# PRU_ICSSG0_PR1_MII_RT_PR1_MII_RT_G_CFG_REGS_G_local register map
Vendor: Texas Instruments
Peripheral module from a debugger description file (folder J7ES).
Registers are 32-bit, read-write, reset 0x0 unless marked. A register's access mark holds for its fields unless they carry their own. Offsets are as the file gives them; lines under a group give offsets from that group; [hi:lo] are bit positions; {n}, {i} and the like mark numbered series; 'fields as' and 'values as' point back to an identical list; <NAME> marks a mode.

## PRU_ICSSG0_PR1_MII_RT_PR1_MII_RT_G_CFG_REGS_G
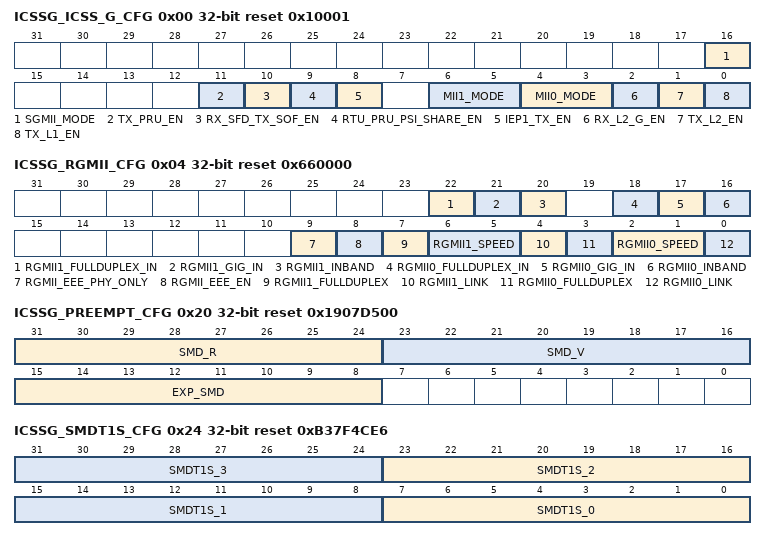
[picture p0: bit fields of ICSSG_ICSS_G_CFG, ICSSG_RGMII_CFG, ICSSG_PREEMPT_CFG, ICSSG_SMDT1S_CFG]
0x00 ICSSG_ICSS_G_CFG reset 0x10001 — ICSS_G SGMII mode is supported only for PRU_ICSSG1 instance.
  [16] SGMII_MODE — SGMII MODE0: Fiber MODE 1: SGMII MODE
  [11] TX_PRU_EN — Enable TX_PRU to gain control of MII TXL2
  [10] RX_SFD_TX_SOF_EN — Enable the remaping of tx_sof to rx_sfd if auto fwd is enable
  [9] RTU_PRU_PSI_SHARE_EN — Enable the sharing of xfr2psi attached to PRU for PRU RTU AND HW FIFO
  [8] IEP1_TX_EN — Enable IEP1 for TX Enable0: Use IEP0 CMP3_4 1: Use IEP1 CMP3_4
  [6:5] MII1_MODE — MII1 MODE0: MII 1: RGMII 2: SGMII
  [4:3] MII0_MODE — MII0 MODE0: MII 1: RGMII 2: SGMII
  [2] RX_L2_G_EN — Enable the RX L2 G features of filter frags of size TBD and backpressure RX L20: Disabled 1: Enabled
  [1] TX_L2_EN — Enable the TX L2 Fifo0: Disabled 1: Enabled
  [0] TX_L1_EN — Enable the TX L1 Fifo0: Disabled 1: Enabled
0x04 ICSSG_RGMII_CFG access per field reset 0x660000 — RGMII
  [22] RGMII1_FULLDUPLEX_IN rw — RGMII Fullduplex overide0: half 1: full
  [21] RGMII1_GIG_IN rw — RGMII GigBit Enable0: 100 Mbs 1: 1000 Mbs
  [20] RGMII1_INBAND rw — RGMII In BandEnable or Force0: InBAND is Disabled 1: InBAND Enable
  [18] RGMII0_FULLDUPLEX_IN rw — RGMII Fullduplex overide0: half 1: full
  [17] RGMII0_GIG_IN rw — RGMII GigBit Enable0: 100 Mbs 1: 1000 Mbs
  [16] RGMII0_INBAND rw — RGMII In BandEnable or Force0: InBAND is Disabled 1: InBAND Enable
  [9] RGMII_EEE_PHY_ONLY rw — RGMII Phy Only Low Power0: disable 1: enable
  [8] RGMII_EEE_EN rw — RGMII Energy Efficient Enable0: disable 1: enable
  [7] RGMII1_FULLDUPLEX ro — RGMII Fullduplex0: half duplex 1: full duplex
  [6:5] RGMII1_SPEED ro — RGMII Speed00: 10Mpbs 01: 100Mpbs 10: 1000 Mpbs
  [4] RGMII1_LINK ro — RGMII Link Status0: link is down 1: link is up
  [3] RGMII0_FULLDUPLEX ro — RGMII Fullduplex0: half duplex 1: full duplex
  [2:1] RGMII0_SPEED ro — RGMII Speed00: 10Mpbs 01: 100Mpbs 10: 1000 Mpbs
  [0] RGMII0_LINK ro — RGMII Link Status0: link is down 1: link is up
0x08 ICSSG_MAC_PRU0_0
  [31:0] MAC_PRU0_0 — MAC pru0 DA3:DA0 Used for SAV and DA match
0x0C ICSSG_MAC_PRU0_1
  [15:0] MAC_PRU0_1 — MAC pru0 DA5:DA4 Used for SAV and DA match
0x10 ICSSG_MAC_PRU1_0
  [31:0] MAC_PRU1_0 — MAC pru1 DA3:DA0 Used for SAV and DA match
0x14 ICSSG_MAC_PRU1_1
  [15:0] MAC_PRU1_1 — MAC pru1 DA5:DA4 Used for SAV and DA match
0x18 ICSSG_MAC_INTERFACE_0 — MAC_Interface_0
  [31:0] MAC_INF_0 — MAC Host interface DA3:DA0 Used for SAV and DA match
0x1C ICSSG_MAC_INTERFACE_1 — MAC_Interface_1
  [15:0] MAC_INF_1 — MAC Host interface DA5:DA4 Used for SAV and DA match
0x20 ICSSG_PREEMPT_CFG reset 0x1907D500 — Preemption_Cfg
  [31:24] SMD_R — Response frame TAG
  [23:16] SMD_V — Verification frame TAG
  [15:8] EXP_SMD — None preemptable frame start, or express frame
0x24 ICSSG_SMDT1S_CFG reset 0xB37F4CE6 — SMDType1SPreemptableFrameStartCfg
  [8n+7:8n] SMDT1S_{n} (n=0..3) — SMDT1S{n} pattern
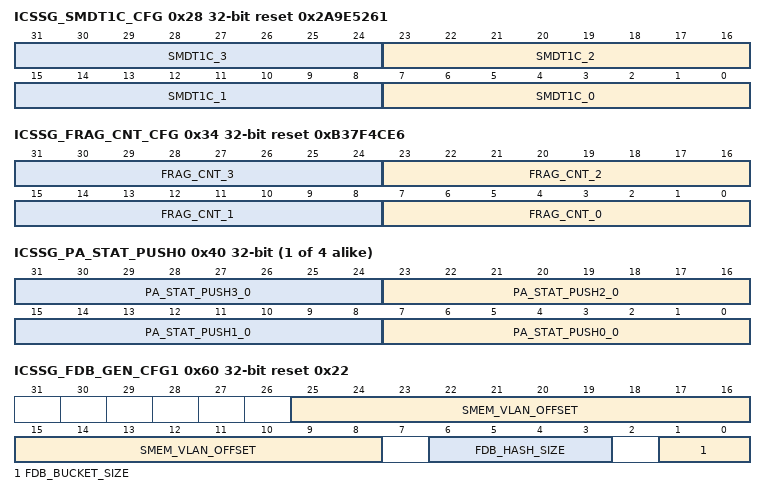
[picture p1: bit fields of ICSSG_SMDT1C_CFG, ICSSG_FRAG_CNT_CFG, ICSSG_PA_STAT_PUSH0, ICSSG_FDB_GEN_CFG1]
0x28 ICSSG_SMDT1C_CFG reset 0x2A9E5261 — SMDType1CNoneInitialFragCfg
  [8n+7:8n] SMDT1C_{n} (n=0..3) — SMDT1C{n} pattern
0x34 ICSSG_FRAG_CNT_CFG reset 0xB37F4CE6 — FragCntCfg
  [8n+7:8n] FRAG_CNT_{n} (n=0..3) — FRAG Cnt{n} pattern
{0x40+4i} ICSSG_PA_STAT_PUSH{i} (i=0..3) — PaStatPush{i}
  [8n+7:8n] PA_STAT_PUSH{n}_{i} (n=0..3) — pa stat push{n}
0x60 ICSSG_FDB_GEN_CFG1 reset 0x22 — FDBCfg1
  [25:8] SMEM_VLAN_OFFSET — SMEM VLAN FID table base address
  [6:3] FDB_HASH_SIZE — FDB hash size0:64 1:128 2:256 3:512 4:1024 5:2048
  [1:0] FDB_BUCKET_SIZE — FDB buket size0:1 1:2 2:4 3:8
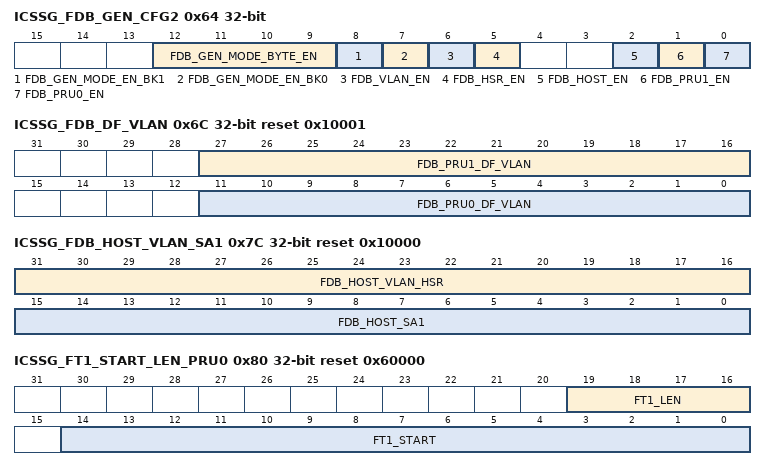
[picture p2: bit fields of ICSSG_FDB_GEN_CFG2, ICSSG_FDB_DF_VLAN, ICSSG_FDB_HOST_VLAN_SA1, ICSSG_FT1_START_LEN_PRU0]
0x64 ICSSG_FDB_GEN_CFG2 — FDBCfg2
  [12:9] FDB_GEN_MODE_BYTE_EN — FDB General Mode Byte compare size0 = 1 Byte, 15 = 16 Bytes
  [8] FDB_GEN_MODE_EN_BK1 — FDB General Mode Enable Bank1 if set PRU0/PRU1/HOST will get disabled
  [7] FDB_GEN_MODE_EN_BK0 — FDB General Mode Enable Bank0 if set PRU0/PRU1/HOST will get disabled
  [6] FDB_VLAN_EN — FDB Global VLAN Enable
  [5] FDB_HSR_EN — FDB Global HSR Enable note VLAN most be disabled
  [2] FDB_HOST_EN — FDB HOST Enable
  [1] FDB_PRU1_EN — FDB PRU1 Enable
  [0] FDB_PRU0_EN — FDB PRU0 Enable
0x68 ICSSG_FDB_GEN_STATUS size not given access not given reset not defined — FDBStatus
0x6C ICSSG_FDB_DF_VLAN reset 0x10001 — FDBDefaultPRUVLAN
  [27:16] FDB_PRU1_DF_VLAN — FDB Default VLAN for PRU1
  [11:0] FDB_PRU0_DF_VLAN — FDB Default VLAN for PRU0
0x70 ICSSG_FDB_HOST_DA0 — FDB_HOST_DA3:0_Cfg
  [31:0] FDB_HOST_DA0 — FDB HOST DA3:0
0x74 ICSSG_FDB_HOST_DA1 — FDB_HOST_DA5:4_Cfg
  [15:0] FDB_HOST_DA1 — FDB HOST DA5:4
0x78 ICSSG_FDB_HOST_SA0 — FDB_HOST_SA3:0_Cfg
  [31:0] FDB_HOST_SA0 — FDB HOST SA3:0
0x7C ICSSG_FDB_HOST_VLAN_SA1 reset 0x10000 — FDB_HOST_VLAN_SA5:4_Cfg
  [31:16] FDB_HOST_VLAN_HSR — FDB HOST VLAN[11:0] OR HSR[15:0]
  [15:0] FDB_HOST_SA1 — FDB HOST SA5:4
0x80 ICSSG_FT1_START_LEN_PRU0 reset 0x60000 — Filter1StartandLengthPru0
  [19:16] FT1_LEN — Defines the total number of Bytes Filter1 will check before Valid bit is set
  [14:0] FT1_START — Byte count start for Filter1.Any wrt will clear all Filter1 Status Bits
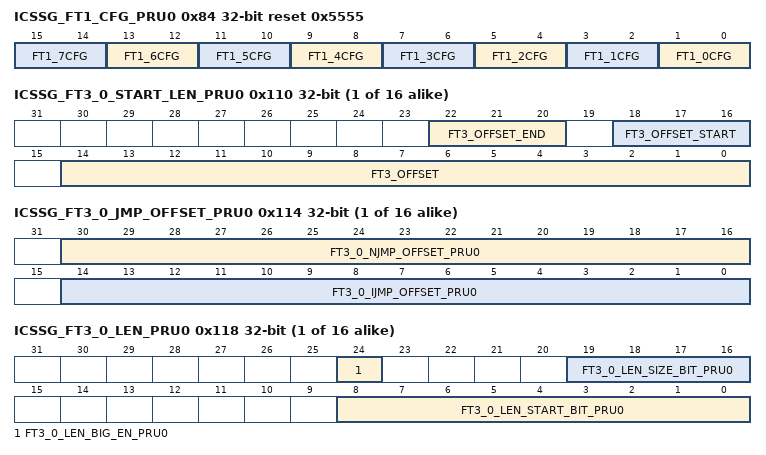
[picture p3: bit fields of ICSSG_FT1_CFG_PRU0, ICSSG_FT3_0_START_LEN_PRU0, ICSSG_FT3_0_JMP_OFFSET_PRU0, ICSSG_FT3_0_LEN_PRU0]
0x84 ICSSG_FT1_CFG_PRU0 reset 0x5555 — Filter1ConfigPru0
  [2n+1:2n] FT1_{n}CFG (n=0..7) — 0: Disabled 1: EQ 2: GT 3: LT
{0x88+0x10*i} ICSSG_FT1_{i}_DA0_PRU0 (i=0..7) — Filter1_{i}_DA0_Pru0
  [31:0] FT1_{i}_DA0 — Filter1 DA4:DA1
{0x8C+0x10*i} ICSSG_FT1_{i}_DA1_PRU0 (i=0..7) — Filter1_{i}_DA1_Pru0
  [15:0] FT1_{i}_DA1 — Filter1 DA6:DA5
{0x90+0x10*i} ICSSG_FT1_{i}_DA_MASK0_PRU0 (i=0..7) — Filter1_{i}_DA0MaskPru0
  [31:0] FT1_{i}_DA_MASK0 — Filter1 MDA4:MDA1 set to 1 to mask that bit
{0x94+0x10*i} ICSSG_FT1_{i}_DA_MASK1_PRU0 (i=0..7) — Filter1_{i}_DA1MaskPru0
  [15:0] FT1_{i}_DA_MASK1 — Filter1 MDA6:MDA5 set to 1 to mask that bit
{0x108+0x20*i} ICSSG_FT3_{i}_START_PRU0 reset 0xC (i=0..15) — Filter3_{i}_StartPru0
  [14:0] FT3_START — Byte count start for Filter3.Any wrt will clear all Filter3 Status Bits SW can read to determine next start during Auto
{0x10C+0x20*i} ICSSG_FT3_{i}_START_AUTO_PRU0 ro (i=0..15) — Filter3_{i}_StartAutoPru0
  [14:0] FT3_START_AUTO — Byte count start for Auto skip mode
{0x110+0x20*i} ICSSG_FT3_{i}_START_LEN_PRU0 (i=0..15) — Filter3_{i}_StartoffsetPru0
  [22:20] FT3_OFFSET_END — Defines which byte within FT3_[N]P[63:0] to end the compare at set the Valid flag, rule ft3_offset_end &gt;= ft3_offset_start To disable pattern compare set start and end to zero
  [18:16] FT3_OFFSET_START — Defines which byte within FT3_[N]P[63:0] to start the compare
  [14:0] FT3_OFFSET — Determine which byte to start FT3_[N]P[63:0] operation it will start on the next byte after FT3_T completes if set to zero
{0x114+0x20*i} ICSSG_FT3_{i}_JMP_OFFSET_PRU0 (i=0..15) — Filter3_{i}_JmpoffsetPru0
  [30:16] FT3_{i}_NJMP_OFFSET_PRU0 — Defines the Next Offset to compare when auto arm jump is enabled
  [14:0] FT3_{i}_IJMP_OFFSET_PRU0 — Defines the Intial Offset to compare when auto arm jump is enabled
{0x118+0x20*i} ICSSG_FT3_{i}_LEN_PRU0 (i=0..15) — Filter3_{i}_LenPru0
  [24] FT3_{i}_LEN_BIG_EN_PRU0 — Enable Big Indian on Length
  [19:16] FT3_{i}_LEN_SIZE_BIT_PRU0 — Defines number of bits to extract the length for the auto skip function
  [8:0] FT3_{i}_LEN_START_BIT_PRU0 — Defines relative bit offset from the HIT byte location upto 512 bit offset the exraction to determine the on the fly length byte offset
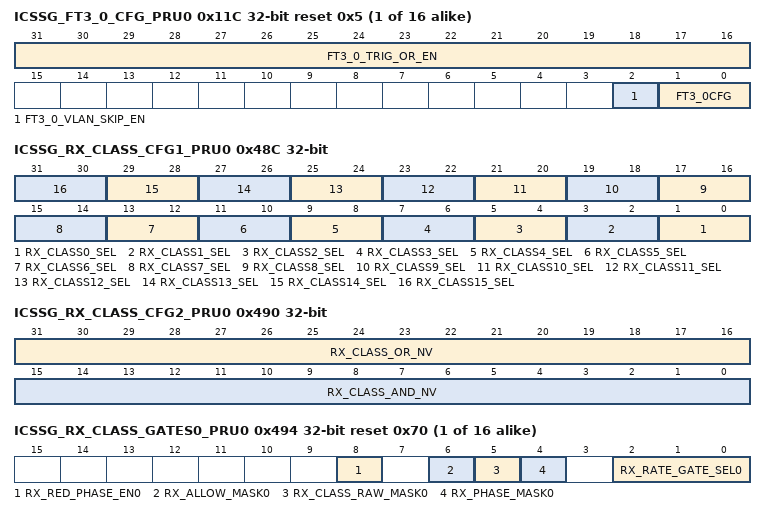
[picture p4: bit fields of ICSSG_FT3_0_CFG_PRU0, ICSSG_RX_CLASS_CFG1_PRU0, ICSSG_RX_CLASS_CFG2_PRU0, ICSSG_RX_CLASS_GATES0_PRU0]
{0x11C+0x20*i} ICSSG_FT3_{i}_CFG_PRU0 reset 0x5 (i=0..15) — Filter3_{i}_ConfigPru0
  [31:16] FT3_{i}_TRIG_OR_EN — Trigger ft3 select for auto skip enable, if one or more set the function is enabled note you can not slect the same ft3 only others
  [2] FT3_{i}_VLAN_SKIP_EN — 0: Disabled 1: Enable
  [1:0] FT3_{i}CFG — 0: Disabled 1: EQ 2: GT 3: LT
{0x120+0x20*i} ICSSG_FT3_{i}_T_PRU0 (i=0..15) — Filter3_{i}_TPru0
  [31:0] FT3_{i}_T — Filter3 T4:T1 Note if Auto Skip is enabled then Type filter is not enabled
{0x124+0x20*i} ICSSG_FT3_{i}_T_MASK_PRU0 (i=0..15) — Filter3_{i}_T_MaskPru0
  [31:0] FT3_{i}_T_MASK — Filter3 MT4:MT1 Note if Auto Skip is enabled then Type filter is not enabled set to 1 to mask that bit
{0x308+0x10*i} ICSSG_FT3_{i}_P0_PRU0 (i=0..15) — Filter3_{i}P0Pru0
  [31:0] FT3_{i}_P0 — Filter3 P4:P1
{0x30C+0x10*i} ICSSG_FT3_{i}_P1_PRU0 (i=0..15) — Filter3_{i}P1Pru0
  [31:0] FT3_{i}_P1 — Filter3 P8:P5
{0x310+0x10*i} ICSSG_FT3_{i}_P_MASK0_PRU0 (i=0..15) — Filter3P_Mask0Pru0
  [31:0] FT3_{i}_P_MASK0 — Filter3 MP4:MP1 set to 1 to mask that bit
{0x314+0x10*i} ICSSG_FT3_{i}_P_MASK1_PRU0 (i=0..15) — Filter3P_Mask1Pru0
  [31:0] FT3_{i}_P_MASK1 — Filter3 MP8:MP5 set to 1 to mask that bit
0x408 ICSSG_FT_RX_PTR_PRU0 — FilterByteCountPru0
  [31:0] FT_RX_PTR_PRU0 — RX current filter Byte Count
{0x40C+8i} ICSSG_RX_CLASS{i}_AND_EN_PRU0 (i=0..15) — rx_class{i}_and_enablesPru0
  [31:0] RX_CLASS{i}_AND_EN — rx class and enabels
{0x410+8i} ICSSG_RX_CLASS{i}_OR_EN_PRU0 (i=0..15) — rx_class{i}_or_enablesPru0
  [31:0] RX_CLASS{i}_OR_EN — rx class or enabels
0x48C ICSSG_RX_CLASS_CFG1_PRU0 — rx_class_cfg1Pru0
  [2n+1:2n] RX_CLASS{n}_SEL (n=0..15) — rx class final term selection00: OR 01: AND 10: OR AND AND OR 11: OR OR AND
0x490 ICSSG_RX_CLASS_CFG2_PRU0 — rx_class_cfg2Pru0
  [31:16] RX_CLASS_OR_NV — rx class or nv enable
  [15:0] RX_CLASS_AND_NV — rx class and nv enable
{0x494+4i} ICSSG_RX_CLASS_GATES{i}_PRU0 reset 0x70 (i=0..15) — rx_class_gate_cfgPru0
  [8] RX_RED_PHASE_EN{i} — red phase neable0: disable 1: enable
  [6] RX_ALLOW_MASK{i} — allow mask0: unmask 1: mask
  [5] RX_CLASS_RAW_MASK{i} — class raw mask0: unmask 1: mask
  [4] RX_PHASE_MASK{i} — time phase mask0: unmask 1: mask
  [2:0] RX_RATE_GATE_SEL{i} — defines which rx_rate will gate rx_class
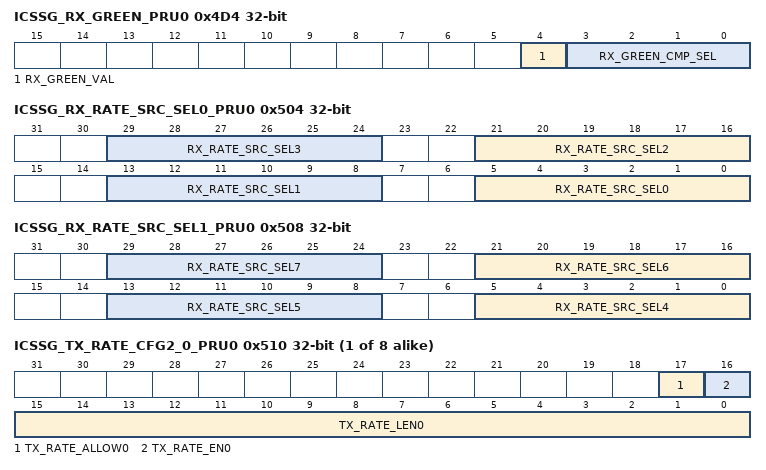
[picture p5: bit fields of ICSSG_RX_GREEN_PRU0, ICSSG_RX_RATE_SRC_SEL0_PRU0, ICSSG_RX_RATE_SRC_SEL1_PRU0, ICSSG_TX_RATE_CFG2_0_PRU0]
0x4D4 ICSSG_RX_GREEN_PRU0 access per field — RX_greenPru0
  [4] RX_GREEN_VAL ro — 0 RED 1 GREEN status
  [3:0] RX_GREEN_CMP_SEL rw — define which IEP CMP start green
0x4D8 ICSSG_SA_HASH_PRU0 — SAHashPru0
  [9:0] SA_HASH_SEED
0x4DC ICSSG_CONN_HASH_PRU0 — ConnectionHashPru0
  [9:0] CONN_HASH_SEED — Connection Hash Seed
0x4E0 ICSSG_CONN_HASH_START_PRU0 — ConnectionHashStartPru0
  [14:0] CONN_HASH_START — Connection Hash Start which 4 Bytes to hash
{0x4E4+4i} ICSSG_RX_RATE_CFG{i}_PRU0 (i=0..7) — RX_RateConfiguration{i}Pru0
  [31:0] RX_RATE_CIR_IDLE{i} — RX Rate Peak Information Rate Idle Increment Value - The number added to the PIR counter every clock cycle including EOF.The PIR counter is disabled with a zero value and packets will not be marked RED
0x504 ICSSG_RX_RATE_SRC_SEL0_PRU0 — RX_RateSourceSelect0Pru0
  [8n+5:8n] RX_RATE_SRC_SEL{n} (n=0..3) — Map which filter/flag/class hit that rate logic uses, see table for mapping
0x508 ICSSG_RX_RATE_SRC_SEL1_PRU0 — RX_RateSourceSelect1Pru0
  [8n-27:8n-32] RX_RATE_SRC_SEL{n} (n=4..7) — Map which filter/flag/class hit that rate logic uses, see table for mapping
{0x50C+8i} ICSSG_TX_RATE_CFG1_{i}_PRU0 (i=0..7) — TX_RateConfiguration1_{i}Pru0
  [31:0] TX_RATE_CIR_IDLE{i} — TX Rate Peak Information Rate Idle Increment Value - The number added to the PIR counter every clock cycle including EOF.The PIR counter is disabled with a zero value and packets will not be marked RED
{0x510+8i} ICSSG_TX_RATE_CFG2_{i}_PRU0 access per field (i=0..7) — TX_RateConfiguration2_{i}Pru0
  [17] TX_RATE_ALLOW{i} ro — TX Rate Pkt Enable
  [16] TX_RATE_EN{i} rw — TX Rate Pkt Enable
  [15:0] TX_RATE_LEN{i} rw — TX Rate Pkt Length
0x54C ICSSG_RX_STAT_GOOD_PRU0 — RXGoodFrameCountPru0
  [31:0] RX_GOOD_FRM_CNT — RX Good Frame Count Inc on none min err max err crc err odd err, Wrt subtracts
0x550 ICSSG_RX_STAT_BC_PRU0 — RXBCFrameCountPru0
  [15:0] RX_BC_FRM_CNT — RX BC Frame Count Inc on BC type, Wrt subtracts
0x554 ICSSG_RX_STAT_MC_PRU0 — RXMCFrameCountPru0
  [15:0] RX_MC_FRM_CNT — RX MC Frame Count Inc on MC type, Wrt subtracts
0x558 ICSSG_RX_STAT_CRC_ERR_PRU0 — RXCRCErrFrameCountPru0
  [15:0] RX_CRC_ERR_FRM_CNT — RX CRC Err Frame Count Inc on crc err, Wrt subtracts
0x55C ICSSG_RX_STAT_MII_ERR_PRU0 — RXMIIErrFrameCountPru0
  [15:0] RX_MII_ERR_FRM_CNT — RX MII Err Frame Count Inc on mii sgmii rgmii err, Wrt subtracts
0x560 ICSSG_RX_STAT_ODD_ERR_PRU0 — RXOddNibbleFrameCountPru0
  [15:0] RX_ODD_ERR_FRM_CNT — RX Odd Nibble Frame Count Inc on odd nibble mii, Wrt subtracts
0x564 ICSSG_RX_STAT_MAX_SIZE_PRU0 reset 0x7D0 — RXMaxSizeFramePru0
  [15:0] RX_MAX_SIZE_FRM — RX MAX Size Frame Count Limit
0x568 ICSSG_RX_STAT_MAX_ERR_PRU0 — RXMaxSizeErrFrameCountPru0
  [15:0] RX_MAX_ERR_FRM_CNT — RX MAX Size Err Frame Count Inc if &gt; than Limit, Wrt subtracts
0x56C ICSSG_RX_STAT_MIN_SIZE_PRU0 reset 0x40 — RXMinSizeFramePru0
  [15:0] RX_MIN_SIZE_FRM — RX MIN Size Frame Limit
0x570 ICSSG_RX_STAT_MIN_ERR_PRU0 — RXMinSizeErrFrameCountPru0
  [15:0] RX_MIN_ERR_FRM_CNT — RX MIN Size Frame Count Inc if &lt; than limit, Wrt subtracts
0x574 ICSSG_RX_STAT_OVERRUN_ERR_PRU0 — RXoverrunFrameCountPru0
  [15:0] RX_OVERRUN_ERR_FRM_CNT — RX L1 FIFO overflow Frame Count Inc on overflow event, Wrt subtracts
{0x578+4i} ICSSG_RX_STAT_CLASS{i}_HIT_PRU0 (i=0..15) — RXClass0
  [31:0] RX_STAT_CLASS{i}_PRU0 — RX Class{i} Hit Count, Wrt subtracts
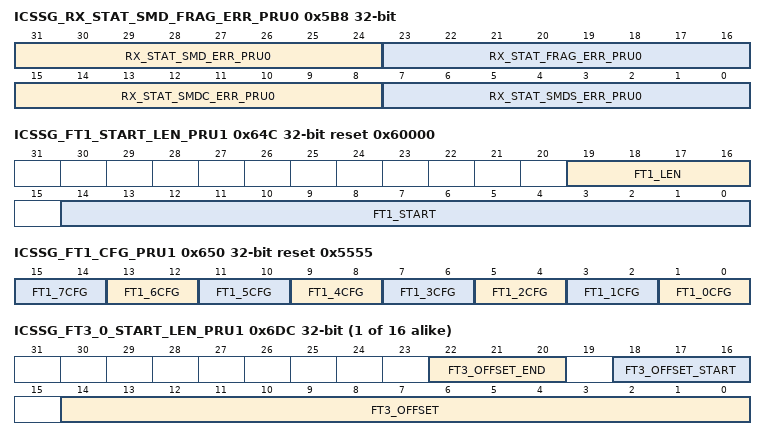
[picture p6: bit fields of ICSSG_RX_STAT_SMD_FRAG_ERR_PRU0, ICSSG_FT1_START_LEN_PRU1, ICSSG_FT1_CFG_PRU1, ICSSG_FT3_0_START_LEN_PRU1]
0x5B8 ICSSG_RX_STAT_SMD_FRAG_ERR_PRU0 — RXSMDFragErrCountPru0
  [31:24] RX_STAT_SMD_ERR_PRU0 — RX SMDS Error Count, Inc when first none 0x55 does not match any valid SMD, Wrt subtracts
  [23:16] RX_STAT_FRAG_ERR_PRU0 — RX Frag_Cnt Seq Error Count, Wrt subtracts
  [15:8] RX_STAT_SMDC_ERR_PRU0 — RX SMDCx Seq Error Count, Wrt subtracts
  [7:0] RX_STAT_SMDS_ERR_PRU0 — RX SMDSx Seq Error Count, Wrt subtracts
0x5BC ICSSG_RX_STAT_BKT1_SIZE_PRU0 reset 0x40 — RXBucket1SizeConfigPru0
  [13:0] RX_STAT_BKT1_SIZE — RX Bucket1 Byte Size
0x5C0 ICSSG_RX_STAT_BKT2_SIZE_PRU0 reset 0x80 — RXBucket2SizeConfigPru0
  [13:0] RX_STAT_BKT2_SIZE — RX Bucket2 Byte Size
0x5C4 ICSSG_RX_STAT_BKT3_SIZE_PRU0 reset 0x100 — RXBucket3SizeConfigPru0
  [13:0] RX_STAT_BKT3_SIZE — RX Bucket3 Byte Size
0x5C8 ICSSG_RX_STAT_BKT4_SIZE_PRU0 reset 0x200 — RXBucket4SizeConfigPru0
  [13:0] RX_STAT_BKT4_SIZE — RX Bucket4 Byte Size
0x5CC ICSSG_RX_STAT_64_PRU0 — RX64BSizedFrameCountPru0
  [15:0] RX_64_FRM_CNT — RX 64Byte Frame Count Inc if 64B size
0x5D0 ICSSG_RX_STAT_BKT1_PRU0 — RXBucket1SizedFrameCountPru0
  [15:0] RX_STAT_BKT1 — RX Bucket1 Frame Count Inc if &lt;= than Bucket1 Byte Size
{0x5CC+4i} ICSSG_RX_STAT_BKT{i}_PRU0 (i=2..4) — RXBucket{i}SizedFrameCountPru0
  [15:0] RX_STAT_BKT{i} — RX Bucket{i} Frame Count Inc if &lt;= than Bucket{i} Byte Size and if &gt; than Bucket{i-1} Byte Size
0x5E0 ICSSG_RX_STAT_BKT5_PRU0 — RXBucket5SizedFrameCountPru0
  [15:0] RX_STAT_BKT5 — RX Bucket5 Frame Count Inc if &gt; than Bucket4 Byte Size
0x5E4 ICSSG_RX_STAT_TOTAL_BYTES_PRU0 — RXTotalByteCountPru0
  [31:0] RX_STAT_TOTAL_BYTES_PRU — RX Total Byte Count
0x5E8 ICSSG_RXTX_STAT_TOTAL_BYTES_PRU0 — RX_TX_TotalByteCountPru0
  [31:0] RXTX_STAT_TOTAL_BYTES_PRU — RX and TX Total Byte Count
0x5EC ICSSG_TX_STAT_GOOD_PORT0 — TXGoodFrameCountPort0
  [31:0] TX_GOOD_FRM_CNT — TX Good Frame Count Inc if no min size err max size err or mii odd nibble
0x5F0 ICSSG_TX_STAT_BC_PORT0 — TXBCFrameCountPort0
  [15:0] TX_BC_FRM_CNT — TX BC Frame Count Inc if BC
0x5F4 ICSSG_TX_STAT_MC_PORT0 — TXMFrameCountPort0
  [15:0] TX_MC_FRM_CNT — TX MC Frame Count Inc if MC
0x5F8 ICSSG_TX_STAT_ODD_ERR_PORT0 — TXOddNibbleFrameCountPort0
  [15:0] TX_ODD_ERR_FRM_CNT — TX Odd Nibble Frame Count Inc if mii odd nibble
0x5FC ICSSG_TX_STAT_UNDERFLOW_ERR_PORT0 — TXUnderFlowErrCountPort0
  [15:0] TX_UNDERFLOW_CNT — TX MAX Underflow Error Cnt
0x600 ICSSG_TX_STAT_MAX_SIZE_PORT0 reset 0x7D0 — TXMaxSizeFramePort0
  [15:0] TX_MAX_SIZE_FRM — TX MAX Size Frame Count Limit
0x604 ICSSG_TX_STAT_MAX_ERR_PORT0 — TXMaxSizeErrFrameCountPort0
  [15:0] TX_MAX_ERR_FRM_CNT — TX MAX Size Err Frame Count Inc if &gt; max Limit
0x608 ICSSG_TX_STAT_MIN_SIZE_PORT0 reset 0x40 — TXMinSizeFramePort0
  [15:0] TX_MIN_SIZE_FRM — TX MIN Size Frame Count Limit
0x60C ICSSG_TX_STAT_MIN_ERR_PORT0 — TXMinSizeErrFrameCountPort0
  [15:0] TX_MIN_ERR_FRM_CNT — TX MIN Size Err Frame Count Inc if &lt; min Limit
0x610 ICSSG_TX_STAT_BKT1_SIZE_PORT0 reset 0x40 — TXBucket1SizeConfigPort0
  [13:0] TX_STAT_BKT1_SIZE — TX Bucket1 Byte Size
0x614 ICSSG_TX_STAT_BKT2_SIZE_PORT0 reset 0x80 — TXBucket2SizeConfigPort0
  [13:0] TX_STAT_BKT2_SIZE — TX Bucket2 Byte Size
0x618 ICSSG_TX_STAT_BKT3_SIZE_PORT0 reset 0x100 — TXBucket3SizeConfigPort0
  [13:0] TX_STAT_BKT3_SIZE — TX Bucket3 Byte Size
0x61C ICSSG_TX_STAT_BKT4_SIZE_PORT0 reset 0x200 — TXBucket4SizeConfigPort0
  [13:0] TX_STAT_BKT4_SIZE — TX Bucket4 Byte Size
0x620 ICSSG_TX_STAT_64_PORT0 — TX64BSizedFrameCountPort0
  [15:0] TX_64_FRM_CNT — TX 64Byte Frame Count Inc if 64B
0x624 ICSSG_TX_STAT_BKT1_PORT0 — TXBucket1SizedFrameCountPort0
  [15:0] TX_STAT_BKT1 — TX Bucket1 Inc if &lt;= than Bucket1
{0x620+4i} ICSSG_TX_STAT_BKT{i}_PORT0 (i=2..4) — TXBucket{i}SizedFrameCountPort0
  [15:0] TX_STAT_BKT{i} — TX Bucket{i} Inc if &lt;= than Bucket{i} Byte Size and if &gt; than Bucket{i-1} Byte Size
0x634 ICSSG_TX_STAT_BKT5_PORT0 — TXBucket5SizedFrameCountPort0
  [15:0] TX_STAT_BKT5 — TX Bucket5 Inc if &gt; than Bucket4 Byte Size
0x638 ICSSG_TX_STAT_TOTAL_BYTES_PORT0 — TXTotalByteCountPort0
  [31:0] TX_TOTAL_STAT_BYTES_PORT — TX Total Byte Count of all Frames
0x63C ICSSG_TX_HSR_TAG_PORT0 reset 0x892F — TXHSRTAGPort0
  [31:0] TX_HSR_TAG — HSR TAG
0x640 ICSSG_TX_HSR_SEQ_PORT0 — TXHSRSeqPort0
  [15:0] TX_HSR_SEQ — HSR Seq count.It will incr for every HSR type
0x644 ICSSG_TX_VLAN_TYPE_TAG_PORT0 reset 0x81 — TXVLANTYPETAGPort0
  [15:0] TX_VLAN_TYPE_TAG — TX VLAN Type Tag, match to enable VLAN removal
0x648 ICSSG_TX_VLAN_INS_TAG_PORT0 reset 0x1 — TXVLANINSTAGPort0
  [31:0] TX_VLAN_INS_TAG — TX VLAN Insertion
0x64C ICSSG_FT1_START_LEN_PRU1 reset 0x60000 — Filter1StartandLengthPru1
  fields as ICSSG_FT1_START_LEN_PRU0
0x650 ICSSG_FT1_CFG_PRU1 reset 0x5555 — Filter1ConfigPru1
  [2n+1:2n] FT1_{n}CFG (n=0..7) — 0: Disabled 1: EQ 2: GT 3: LT
{0x654+0x10*i} ICSSG_FT1_{i}_DA0_PRU1 (i=0..7) — Filter1_{i}_DA0_Pru1
  [31:0] FT1_{i}_DA0 — Filter1 DA4:DA1
{0x658+0x10*i} ICSSG_FT1_{i}_DA1_PRU1 (i=0..7) — Filter1_{i}_DA1_Pru1
  [15:0] FT1_{i}_DA1 — Filter1 DA6:DA5
{0x65C+0x10*i} ICSSG_FT1_{i}_DA_MASK0_PRU1 (i=0..7) — Filter1_{i}_DA0MaskPru1
  fields as ICSSG_FT1_0_DA_MASK0_PRU0
{0x660+0x10*i} ICSSG_FT1_{i}_DA_MASK1_PRU1 (i=0..7) — Filter1_{i}_DA1MaskPru1
  fields as ICSSG_FT1_0_DA_MASK1_PRU0
{0x6D4+0x20*i} ICSSG_FT3_{i}_START_PRU1 reset 0xC (i=0..15) — Filter3_{i}_StartPru1
  fields as ICSSG_FT3_0_START_PRU0
{0x6D8+0x20*i} ICSSG_FT3_{i}_START_AUTO_PRU1 ro (i=0..15) — Filter3_{i}_StartAutoPru1
  [14:0] FT3_START_AUTO — Byte count start for Auto skip mode
{0x6DC+0x20*i} ICSSG_FT3_{i}_START_LEN_PRU1 (i=0..15) — Filter3_{i}_StartoffsetPru1
  fields as ICSSG_FT3_0_START_LEN_PRU0
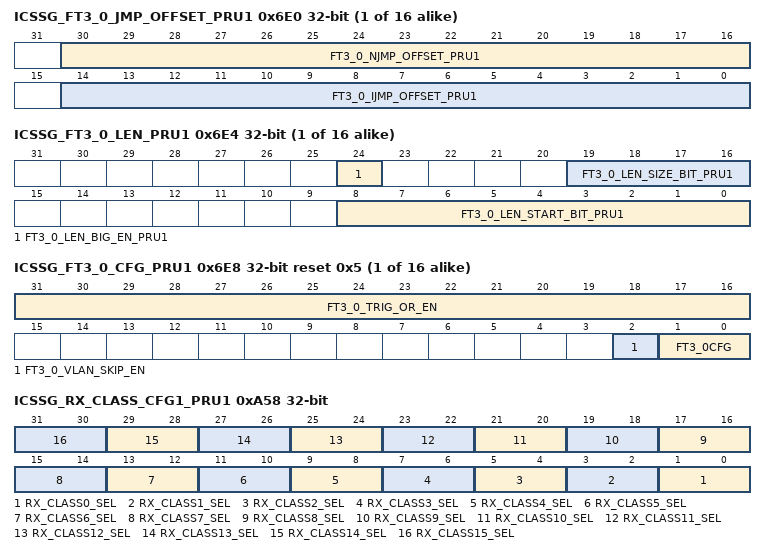
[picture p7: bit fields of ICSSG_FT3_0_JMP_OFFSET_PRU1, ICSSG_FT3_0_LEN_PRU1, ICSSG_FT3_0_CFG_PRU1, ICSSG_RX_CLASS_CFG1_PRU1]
{0x6E0+0x20*i} ICSSG_FT3_{i}_JMP_OFFSET_PRU1 (i=0..15) — Filter3_{i}_JmpoffsetPru1
  [30:16] FT3_{i}_NJMP_OFFSET_PRU1 — Defines the Next Offset to compare when auto arm jump is enabled
  [14:0] FT3_{i}_IJMP_OFFSET_PRU1 — Defines the Intial Offset to compare when auto arm jump is enabled
{0x6E4+0x20*i} ICSSG_FT3_{i}_LEN_PRU1 (i=0..15) — Filter3_{i}_LenPru1
  [24] FT3_{i}_LEN_BIG_EN_PRU1 — Enable Big Indian on Length
  [19:16] FT3_{i}_LEN_SIZE_BIT_PRU1 — Defines number of bits to extract the length for the auto skip function
  [8:0] FT3_{i}_LEN_START_BIT_PRU1 — Defines relative bit offset from the HIT byte location upto 512 bit offset the exraction to determine the on the fly length byte offset
{0x6E8+0x20*i} ICSSG_FT3_{i}_CFG_PRU1 reset 0x5 (i=0..15) — Filter3_{i}_ConfigPru1
  fields as ICSSG_FT3_0_CFG_PRU0
{0x6EC+0x20*i} ICSSG_FT3_{i}_T_PRU1 (i=0..15) — Filter3_{i}_TPru1
  fields as ICSSG_FT3_0_T_PRU0
{0x6F0+0x20*i} ICSSG_FT3_{i}_T_MASK_PRU1 (i=0..15) — Filter3_{i}_T_MaskPru1
  fields as ICSSG_FT3_0_T_MASK_PRU0
{0x8D4+0x10*i} ICSSG_FT3_{i}_P0_PRU1 (i=0..15) — Filter3_{i}P0Pru1
  [31:0] FT3_{i}_P0 — Filter3 P4:P1
{0x8D8+0x10*i} ICSSG_FT3_{i}_P1_PRU1 (i=0..15) — Filter3_{i}P1Pru1
  [31:0] FT3_{i}_P1 — Filter3 P8:P5
{0x8DC+0x10*i} ICSSG_FT3_{i}_P_MASK0_PRU1 (i=0..15) — Filter3P_Mask0Pru1
  [31:0] FT3_{i}_P_MASK0 — Filter3 MP4:MP1 set to 1 to mask that bit
{0x8E0+0x10*i} ICSSG_FT3_{i}_P_MASK1_PRU1 (i=0..15) — Filter3P_Mask1Pru1
  [31:0] FT3_{i}_P_MASK1 — Filter3 MP8:MP5 set to 1 to mask that bit
0x9D4 ICSSG_FT_RX_PTR_PRU1 — FilterByteCountPru1
  [31:0] FT_RX_PTR_PRU1 — RX current filter Byte Count
{0x9D8+8i} ICSSG_RX_CLASS{i}_AND_EN_PRU1 (i=0..15) — rx_class{i}_and_enablesPru1
  [31:0] RX_CLASS{i}_AND_EN — rx class and enabels
{0x9DC+8i} ICSSG_RX_CLASS{i}_OR_EN_PRU1 (i=0..15) — rx_class{i}_or_enablesPru1
  [31:0] RX_CLASS{i}_OR_EN — rx class or enabels
0xA58 ICSSG_RX_CLASS_CFG1_PRU1 — rx_class_cfg1Pru1
  fields as ICSSG_RX_CLASS_CFG1_PRU0
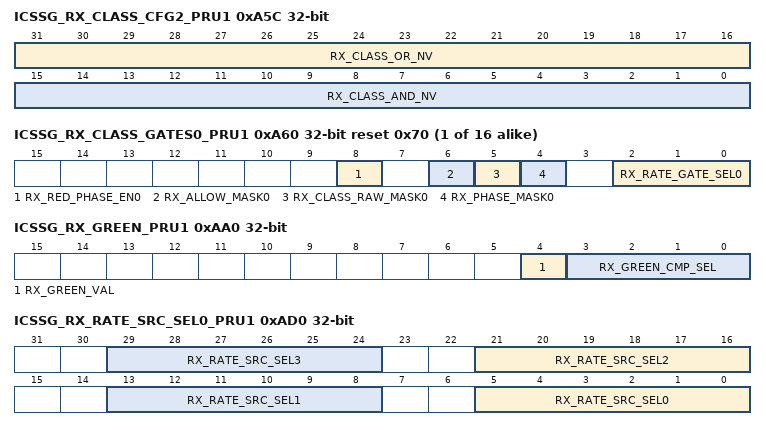
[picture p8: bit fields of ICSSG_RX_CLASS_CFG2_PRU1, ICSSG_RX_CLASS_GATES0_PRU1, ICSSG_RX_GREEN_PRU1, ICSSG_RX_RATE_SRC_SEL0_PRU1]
0xA5C ICSSG_RX_CLASS_CFG2_PRU1 — rx_class_cfg2Pru1
  fields as ICSSG_RX_CLASS_CFG2_PRU0
{0xA60+4i} ICSSG_RX_CLASS_GATES{i}_PRU1 reset 0x70 (i=0..15) — rx_class_gate_cfgPru1
  fields as ICSSG_RX_CLASS_GATES0_PRU0
0xAA0 ICSSG_RX_GREEN_PRU1 access per field — RX_greenPru1
  fields as ICSSG_RX_GREEN_PRU0
0xAA4 ICSSG_SA_HASH_PRU1 — SAHashPru1
  [9:0] SA_HASH_SEED
0xAA8 ICSSG_CONN_HASH_PRU1 — ConnectionHashPru1
  [9:0] CONN_HASH_SEED — Connection Hash Seed
0xAAC ICSSG_CONN_HASH_START_PRU1 — ConnectionHashStartPru1
  [14:0] CONN_HASH_START — Connection Hash Start which 4 Bytes to hash
{0xAB0+4i} ICSSG_RX_RATE_CFG{i}_PRU1 (i=0..7) — RX_RateConfiguration{i}Pru1
  fields as ICSSG_RX_RATE_CFG0_PRU0
0xAD0 ICSSG_RX_RATE_SRC_SEL0_PRU1 — RX_RateSourceSelect0Pru1
  fields as ICSSG_RX_RATE_SRC_SEL0_PRU0
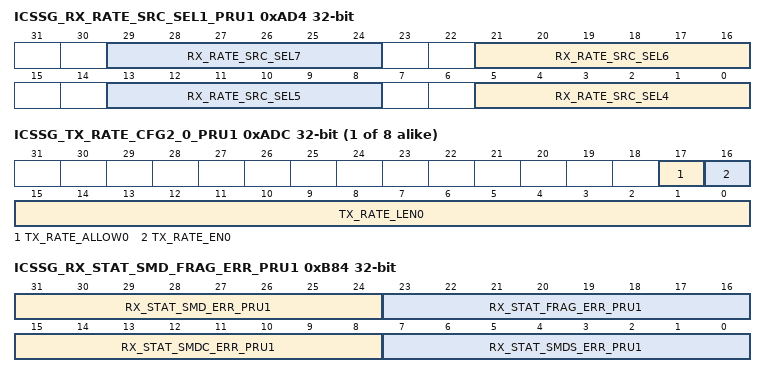
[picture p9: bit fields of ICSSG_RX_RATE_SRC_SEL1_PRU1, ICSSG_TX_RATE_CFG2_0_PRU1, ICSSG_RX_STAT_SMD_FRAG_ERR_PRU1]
0xAD4 ICSSG_RX_RATE_SRC_SEL1_PRU1 — RX_RateSourceSelect1Pru1
  fields as ICSSG_RX_RATE_SRC_SEL1_PRU0
{0xAD8+8i} ICSSG_TX_RATE_CFG1_{i}_PRU1 (i=0..7) — TX_RateConfiguration1_{i}Pru1
  fields as ICSSG_TX_RATE_CFG1_0_PRU0
{0xADC+8i} ICSSG_TX_RATE_CFG2_{i}_PRU1 access per field (i=0..7) — TX_RateConfiguration2_{i}Pru1
  fields as ICSSG_TX_RATE_CFG2_0_PRU0
0xB18 ICSSG_RX_STAT_GOOD_PRU1 — RXGoodFrameCountPru1
  fields as ICSSG_RX_STAT_GOOD_PRU0
0xB1C ICSSG_RX_STAT_BC_PRU1 — RXBCFrameCountPru1
  fields as ICSSG_RX_STAT_BC_PRU0
0xB20 ICSSG_RX_STAT_MC_PRU1 — RXMCFrameCountPru1
  fields as ICSSG_RX_STAT_MC_PRU0
0xB24 ICSSG_RX_STAT_CRC_ERR_PRU1 — RXCRCErrFrameCountPru1
  fields as ICSSG_RX_STAT_CRC_ERR_PRU0
0xB28 ICSSG_RX_STAT_MII_ERR_PRU1 — RXMIIErrFrameCountPru1
  fields as ICSSG_RX_STAT_MII_ERR_PRU0
0xB2C ICSSG_RX_STAT_ODD_ERR_PRU1 — RXOddNibbleFrameCountPru1
  fields as ICSSG_RX_STAT_ODD_ERR_PRU0
0xB30 ICSSG_RX_STAT_MAX_SIZE_PRU1 reset 0x7D0 — RXMaxSizeFramePru1
  [15:0] RX_MAX_SIZE_FRM — RX MAX Size Frame Count Limit
0xB34 ICSSG_RX_STAT_MAX_ERR_PRU1 — RXMaxSizeErrFrameCountPru1
  fields as ICSSG_RX_STAT_MAX_ERR_PRU0
0xB38 ICSSG_RX_STAT_MIN_SIZE_PRU1 reset 0x40 — RXMinSizeFramePru1
  [15:0] RX_MIN_SIZE_FRM — RX MIN Size Frame Limit
0xB3C ICSSG_RX_STAT_MIN_ERR_PRU1 — RXMinSizeErrFrameCountPru1
  fields as ICSSG_RX_STAT_MIN_ERR_PRU0
0xB40 ICSSG_RX_STAT_OVERRUN_ERR_PRU1 — RXoverrunFrameCountPru1
  fields as ICSSG_RX_STAT_OVERRUN_ERR_PRU0
{0xB44+4i} ICSSG_RX_STAT_CLASS{i}_HIT_PRU1 (i=0..15) — RXClass1
  [31:0] RX_STAT_CLASS{i}_PRU1 — RX Class{i} Hit Count, Wrt subtracts
0xB84 ICSSG_RX_STAT_SMD_FRAG_ERR_PRU1 — RXSMDFragErrCountPru1
  [31:24] RX_STAT_SMD_ERR_PRU1 — RX SMDS Error Count, Inc when first none 0x55 does not match any valid SMD, Wrt subtracts
  [23:16] RX_STAT_FRAG_ERR_PRU1 — RX Frag_Cnt Seq Error Count, Wrt subtracts
  [15:8] RX_STAT_SMDC_ERR_PRU1 — RX SMDCx Seq Error Count, Wrt subtracts
  [7:0] RX_STAT_SMDS_ERR_PRU1 — RX SMDSx Seq Error Count, Wrt subtracts
0xB88 ICSSG_RX_STAT_BKT1_SIZE_PRU1 reset 0x40 — RXBucket1SizeConfigPru1
  [13:0] RX_STAT_BKT1_SIZE — RX Bucket1 Byte Size
0xB8C ICSSG_RX_STAT_BKT2_SIZE_PRU1 reset 0x80 — RXBucket2SizeConfigPru1
  [13:0] RX_STAT_BKT2_SIZE — RX Bucket2 Byte Size
0xB90 ICSSG_RX_STAT_BKT3_SIZE_PRU1 reset 0x100 — RXBucket3SizeConfigPru1
  [13:0] RX_STAT_BKT3_SIZE — RX Bucket3 Byte Size
0xB94 ICSSG_RX_STAT_BKT4_SIZE_PRU1 reset 0x200 — RXBucket4SizeConfigPru1
  [13:0] RX_STAT_BKT4_SIZE — RX Bucket4 Byte Size
0xB98 ICSSG_RX_STAT_64_PRU1 — RX64BSizedFrameCountPru1
  [15:0] RX_64_FRM_CNT — RX 64Byte Frame Count Inc if 64B size
0xB9C ICSSG_RX_STAT_BKT1_PRU1 — RXBucket1SizedFrameCountPru1
  fields as ICSSG_RX_STAT_BKT1_PRU0
{0xB98+4i} ICSSG_RX_STAT_BKT{i}_PRU1 (i=2..4) — RXBucket{i}SizedFrameCountPru1
  fields as ICSSG_RX_STAT_BKT2_PRU0
0xBAC ICSSG_RX_STAT_BKT5_PRU1 — RXBucket5SizedFrameCountPru1
  fields as ICSSG_RX_STAT_BKT5_PRU0
0xBB0 ICSSG_RX_STAT_TOTAL_BYTES_PRU1 — RXTotalByteCountPru1
  [31:0] RX_STAT_TOTAL_BYTES_PRU — RX Total Byte Count
0xBB4 ICSSG_RXTX_STAT_TOTAL_BYTES_PRU1 — RX_TX_TotalByteCountPru1
  [31:0] RXTX_STAT_TOTAL_BYTES_PRU — RX and TX Total Byte Count
0xBB8 ICSSG_TX_STAT_GOOD_PORT1 — TXGoodFrameCountPort1
  fields as ICSSG_TX_STAT_GOOD_PORT0
0xBBC ICSSG_TX_STAT_BC_PORT1 — TXBCFrameCountPort1
  [15:0] TX_BC_FRM_CNT — TX BC Frame Count Inc if BC
0xBC0 ICSSG_TX_STAT_MC_PORT1 — TXMFrameCountPort1
  [15:0] TX_MC_FRM_CNT — TX MC Frame Count Inc if MC
0xBC4 ICSSG_TX_STAT_ODD_ERR_PORT1 — TXOddNibbleFrameCountPort1
  fields as ICSSG_TX_STAT_ODD_ERR_PORT0
0xBC8 ICSSG_TX_STAT_UNDERFLOW_ERR_PORT1 — TXUnderFlowErrCountPort1
  [15:0] TX_UNDERFLOW_CNT — TX MAX Underflow Error Cnt
0xBCC ICSSG_TX_STAT_MAX_SIZE_PORT1 reset 0x7D0 — TXMaxSizeFramePort1
  [15:0] TX_MAX_SIZE_FRM — TX MAX Size Frame Count Limit
0xBD0 ICSSG_TX_STAT_MAX_ERR_PORT1 — TXMaxSizeErrFrameCountPort1
  fields as ICSSG_TX_STAT_MAX_ERR_PORT0
0xBD4 ICSSG_TX_STAT_MIN_SIZE_PORT1 reset 0x40 — TXMinSizeFramePort1
  [15:0] TX_MIN_SIZE_FRM — TX MIN Size Frame Count Limit
0xBD8 ICSSG_TX_STAT_MIN_ERR_PORT1 — TXMinSizeErrFrameCountPort1
  fields as ICSSG_TX_STAT_MIN_ERR_PORT0
0xBDC ICSSG_TX_STAT_BKT1_SIZE_PORT1 reset 0x40 — TXBucket1SizeConfigPort1
  [13:0] TX_STAT_BKT1_SIZE — TX Bucket1 Byte Size
0xBE0 ICSSG_TX_STAT_BKT2_SIZE_PORT1 reset 0x80 — TXBucket2SizeConfigPort1
  [13:0] TX_STAT_BKT2_SIZE — TX Bucket2 Byte Size
0xBE4 ICSSG_TX_STAT_BKT3_SIZE_PORT1 reset 0x100 — TXBucket3SizeConfigPort1
  [13:0] TX_STAT_BKT3_SIZE — TX Bucket3 Byte Size
0xBE8 ICSSG_TX_STAT_BKT4_SIZE_PORT1 reset 0x200 — TXBucket4SizeConfigPort1
  [13:0] TX_STAT_BKT4_SIZE — TX Bucket4 Byte Size
0xBEC ICSSG_TX_STAT_64_PORT1 — TX64BSizedFrameCountPort1
  [15:0] TX_64_FRM_CNT — TX 64Byte Frame Count Inc if 64B
0xBF0 ICSSG_TX_STAT_BKT1_PORT1 — TXBucket1SizedFrameCountPort1
  [15:0] TX_STAT_BKT1 — TX Bucket1 Inc if &lt;= than Bucket1
{0xBEC+4i} ICSSG_TX_STAT_BKT{i}_PORT1 (i=2..4) — TXBucket{i}SizedFrameCountPort1
  fields as ICSSG_TX_STAT_BKT2_PORT0
0xC00 ICSSG_TX_STAT_BKT5_PORT1 — TXBucket5SizedFrameCountPort1
  [15:0] TX_STAT_BKT5 — TX Bucket5 Inc if &gt; than Bucket4 Byte Size
0xC04 ICSSG_TX_STAT_TOTAL_BYTES_PORT1 — TXTotalByteCountPort1
  [31:0] TX_TOTAL_STAT_BYTES_PORT — TX Total Byte Count of all Frames
0xC08 ICSSG_TX_HSR_TAG_PORT1 reset 0x892F — TXHSRTAGPort1
  [31:0] TX_HSR_TAG — HSR TAG
0xC0C ICSSG_TX_HSR_SEQ_PORT1 — TXHSRSeqPort1
  [15:0] TX_HSR_SEQ — HSR Seq count.It will incr for every HSR type
0xC10 ICSSG_TX_VLAN_TYPE_TAG_PORT1 reset 0x81 — TXVLANTYPETAGPort1
  fields as ICSSG_TX_VLAN_TYPE_TAG_PORT0
0xC14 ICSSG_TX_VLAN_INS_TAG_PORT1 reset 0x1 — TXVLANINSTAGPort1
  [31:0] TX_VLAN_INS_TAG — TX VLAN Insertion
{0xD00+4i} ICSSG_QUEUE{i} (i=0..63) — Queue{i}
  [15:0] QUEUE_H_PTR{i} — Queue {i}
{0xE00+4i} ICSSG_QUEUE_PEEK{i} ro (i=0..15) — QueuePeek{i}
  [15:0] QUEUE_H_PEEK_PTR{i} — Queue {i} Peek portal
